# WKUP_CTRL_MMR0_WKUP_CTRL_MMR_CFG0_43000000h register map
Vendor: Texas Instruments
Peripheral module from a debugger description file (folder AM275x).
Registers are 32-bit, read-write, reset 0x0 unless marked. A register's access mark holds for its fields unless they carry their own. Offsets are as the file gives them; lines under a group give offsets from that group; [hi:lo] are bit positions; {n}, {i} and the like mark numbered series; 'fields as' and 'values as' point back to an identical list; <NAME> marks a mode.

## wkup_ctrl_mmr_CFG0 (part 1 of 3)
0x8340 WKUP_CTRL_MMRCFG0_WKUP_WWD0_CTRL — RM WWDT Clock Manager Control Register
  [3:0] WKUP_WWD0_CTRL_WWD_STOP — Controls Clocks to the WWD Watchdog CounterField values (others are reserved):4'b0000 - WWD Counter Running4'b1010 - WWD Counter Stopped Reset Source: mod_g_rst_n
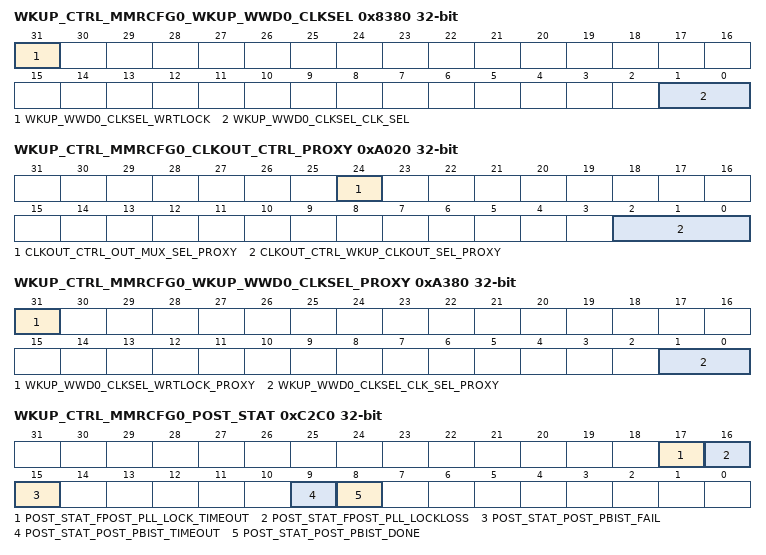
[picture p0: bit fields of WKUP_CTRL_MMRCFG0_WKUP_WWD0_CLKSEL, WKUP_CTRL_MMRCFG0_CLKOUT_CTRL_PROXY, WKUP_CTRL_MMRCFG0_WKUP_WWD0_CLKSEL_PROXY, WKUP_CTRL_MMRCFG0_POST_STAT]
0x8380 WKUP_CTRL_MMRCFG0_WKUP_WWD0_CLKSEL — RM WWDT Clock Manager Clock Selection Register
  [31] WKUP_WWD0_CLKSEL_WRTLOCK — When set, locks WKUP_WWD0_CLKSEL from further writes until the next module reset.Field values (others are reserved):1'b0 - UNLOCKED1'b1 - LOCKED Reset Source: mod_g_rst_n
  [1:0] WKUP_WWD0_CLKSEL_CLK_SEL — Windowed watchdog timer functional clock input select mux controlField values (others are reserved):2'b00 - HFOSC0_CLKOUT2'b01 - DEVICE_CLKOUT_32K2'b10 - CLK_12M_RC2'b11 - CLK_32K Reset Source: mod_g_rst_n
0x8600 WKUP_CTRL_MMRCFG0_WKUP_RTC_CLKSEL — Controls the functional source clock for RTC
  [0] WKUP_RTC_CLKSEL_CLK_SEL — Selects the source of the RTC functional clockField values (others are reserved):1'b0 - DEVICE_CLKOUT_32K1'b1 - CLK_32K_RC Reset Source: mod_por_rst_n
0x9100 WKUP_CTRL_MMRCFG0_CLAIMREG_P2_R0_READONLY ro
  [31:0] CLAIMREG_P2_R0_READONLY — Claim bits for Partition 2 Reset Source: mod_g_rst_n
0x910C WKUP_CTRL_MMRCFG0_CLAIMREG_P2_R3_READONLY ro
  [31:0] CLAIMREG_P2_R3_READONLY — Claim bits for Partition 2 Reset Source: mod_g_rst_n
0x9118 WKUP_CTRL_MMRCFG0_CLAIMREG_P2_R6_READONLY ro
  [31:0] CLAIMREG_P2_R6_READONLY — Claim bits for Partition 2 Reset Source: mod_g_rst_n
0x911C WKUP_CTRL_MMRCFG0_CLAIMREG_P2_R7_READONLY ro
  [31:0] CLAIMREG_P2_R7_READONLY — Claim bits for Partition 2 Reset Source: mod_g_rst_n
0x9130 WKUP_CTRL_MMRCFG0_CLAIMREG_P2_R12_READONLY ro
  [31:0] CLAIMREG_P2_R12_READONLY — Claim bits for Partition 2 Reset Source: mod_g_rst_n
0xA010 WKUP_CTRL_MMRCFG0_WKUP_CLKSEL_PROXY — Selects the functional clock source for the WKUP Domain
  [0] WKUP_CLKSEL_CLK_SEL_PROXY — Selects Clock Source for Wakeup Domain (Device Manager and Peripherals)Field values (others are reserved):1'b0 - CPU_MAIN_PLL15_HSDIV2_CLKOUT__PERIPHERALS_ MAIN_PLL15_HSDIV0_CLKOUT1'b0 - MAIN_PLL15_HSDIV0_CLKOUT0 (HSM_DM_CLK)1'b1 - CPU_AND_PERIPHERALS_MCU_PLL0_HSDIV0_CLKOUT1'b1 - MCU_PLL0_HSDIV0_CKLOUT (MCU_SYSCLK0) Reset Source: mod_g_rst_n
0xA020 WKUP_CTRL_MMRCFG0_CLKOUT_CTRL_PROXY — Enables and selects clock source of WKUP_CLKOUT pin
  [24] CLKOUT_CTRL_OUT_MUX_SEL_PROXY — WKUP CLKOUT (Pin) pin output mux selection. HFOSC0_CLK is a direct output from the HFOSC0Field values (others are reserved):1'b0 - CLK_DIV_OUT1'b1 - HFOSC0_CLK (clk_sel must be DRIVE_LOW) Reset Source: mod_por_rst_n
  [2:0] CLKOUT_CTRL_WKUP_CLKOUT_SEL_PROXY — Controls WKUP CLKOUT MUX for WKUP_CLKOUT0 PinField values (others are reserved):3'b000 - HFOSC0_CLKOUT_SERDES3'b000 - DRIVE_LOW3'b001 - LFOSC0_CLKOUT3'b010 - MAIN_PLL0_HSDIV2_CLKOUT3'b011 - MAIN_PLL1_HSDIV2_CLKOUT3'b100 - MAIN_PLL2_HSDIV9_CLKOUT3'b101 - DEVICE_CLKOUT_32K3'b110 - CLK_12M_RC3'b111 - HFOSC0_CLKOUT Reset Source: mod_por_rst_n
0xA030 WKUP_CTRL_MMRCFG0_WKUP_GTC_CLKSEL_PROXY reset 0x1 — Selects the timebase clock source for the Global Timebase Counter
  [2:0] WKUP_GTC_CLKSEL_CLK_SEL_PROXY — Selects the GTC timebase clock sourceField values (others are reserved):3'b000 - MAIN_PLL2_HSDIV5_CLKOUT3'b001 - MAIN_PLL0_HSDIV6_CLKOUT3'b010 - CP_GEMAC_CPTS0_RFT_CLK (Pin)3'b011 - Reserved '0'3'b100 - MCU_EXT_REFCLK0 (Pin)3'b101 - EXT_REFCLK1 (Pin)3'b110 - MCU_SYSCLK0_DIV23'b110 - MCU_SYSCLK0/23'b111 - MAIN_SYSCLK0 Reset Source: mod_g_rst_n
0xA190 WKUP_CTRL_MMRCFG0_USB0_CLKSEL_PROXY — Selects the functional clock sources for USB0
  [0] USB0_CLKSEL_REFCLK_SEL_PROXY — Selects the clock source for the USB0 ref_clk. Field values (others are reserved):1'b0 - HFOSC0_CLKOUT1'b1 - MAIN_PLL0_HSDIV8_CLKOUT Reset Source: mod_g_rst_n
0xA1B0 WKUP_CTRL_MMRCFG0_WKUP_TIMER0_CLKSEL_PROXY — Timer0 functional clock selection control
  [2:0] WKUP_TIMER0_CLKSEL_CLK_SEL_PROXY — Timer functional clock input select mux controlField values (others are reserved):3'b000 - HFOSC0_CLKOUT3'b001 - DM_CLK/23'b001 - DM_CLK/43'b010 - CLK_12M_RC3'b011 - MCU_PLL0_HSDIV5_CLKOUT3'b100 - MCU_EXT_REFCLK0 (Pin)3'b101 - DEVICE_CLKOUT_32K3'b110 - CPSW0_CPTS_GENF03'b111 - CLK_32K_RC Reset Source: sys_por_rst_n
0xA1B4 WKUP_CTRL_MMRCFG0_WKUP_TIMER1_CLKSEL_PROXY — Timer1 functional clock selection control
  [2:0] WKUP_TIMER1_CLKSEL_CLK_SEL_PROXY — Timer functional clock input select mux controlField values (others are reserved):3'b000 - HFOSC0_CLKOUT3'b001 - DM_CLK/23'b001 - DM_CLK/43'b010 - CLK_12M_RC3'b011 - MCU_PLL0_HSDIV5_CLKOUT3'b100 - MCU_EXT_REFCLK0 (Pin)3'b101 - DEVICE_CLKOUT_32K3'b110 - CPSW0_CPTS_GENF03'b111 - CLK_32K_RC Reset Source: sys_por_rst_n
0xA340 WKUP_CTRL_MMRCFG0_WKUP_WWD0_CTRL_PROXY — RM WWDT Clock Manager Control Register
  [3:0] WKUP_WWD0_CTRL_WWD_STOP_PROXY — Controls Clocks to the WWD Watchdog CounterField values (others are reserved):4'b0000 - WWD Counter Running4'b1010 - WWD Counter Stopped Reset Source: mod_g_rst_n
0xA380 WKUP_CTRL_MMRCFG0_WKUP_WWD0_CLKSEL_PROXY — RM WWDT Clock Manager Clock Selection Register
  [31] WKUP_WWD0_CLKSEL_WRTLOCK_PROXY — When set, locks WKUP_WWD0_CLKSEL from further writes until the next module reset.Field values (others are reserved):1'b0 - UNLOCKED1'b1 - LOCKED Reset Source: mod_g_rst_n
  [1:0] WKUP_WWD0_CLKSEL_CLK_SEL_PROXY — Windowed watchdog timer functional clock input select mux controlField values (others are reserved):2'b00 - HFOSC0_CLKOUT2'b01 - DEVICE_CLKOUT_32K2'b10 - CLK_12M_RC2'b11 - CLK_32K Reset Source: mod_g_rst_n
0xA600 WKUP_CTRL_MMRCFG0_WKUP_RTC_CLKSEL_PROXY — Controls the functional source clock for RTC
  [0] WKUP_RTC_CLKSEL_CLK_SEL_PROXY — Selects the source of the RTC functional clockField values (others are reserved):1'b0 - DEVICE_CLKOUT_32K1'b1 - CLK_32K_RC Reset Source: mod_por_rst_n
{0xB100+4i} WKUP_CTRL_MMRCFG0_CLAIMREG_P2_R{i} (i=0..12)
  [31:0] CLAIMREG_P2_R{i} — Claim bits for Partition 2 Reset Source: mod_g_rst_n
0xC2C0 WKUP_CTRL_MMRCFG0_POST_STAT ro — Contains the result of power-on self tests.
  [17] POST_STAT_FPOST_PLL_LOCK_TIMEOUT — Differentiates between Fast POST and Slow POST. Fast POST is initiated after the PLL locks using the settings in the POST_CFG MMR. Otherwise, if the PLL lock times out, Slow POST is initated at the PLL reference clock rate.Field values (others are reserved):1'b0 - FAST_POST1'b1 - SLOW_POST Reset Source: mod_por_rst_n
  [16] POST_STAT_FPOST_PLL_LOCKLOSS — Indicates that POST exited with a PLL Lockloss ErrorField values (others are reserved):1'b0 - UNKNOWN1'b1 - EXITED_ON_LOCK_LOSS Reset Source: mod_por_rst_n
  [15] POST_STAT_POST_PBIST_FAIL — POST PBIST failedField values (others are reserved):1'b0 - UNKNOWN1'b1 - FAIL Reset Source: mod_por_rst_n
  [9] POST_STAT_POST_PBIST_TIMEOUT — POST PBIST timed outField values (others are reserved):1'b0 - UNKNOWN1'b1 - TIMEOUT Reset Source: mod_por_rst_n
  [8] POST_STAT_POST_PBIST_DONE — POST PBIST doneField values (others are reserved):1'b0 - UNKNOWN1'b1 - DONE Reset Source: mod_por_rst_n
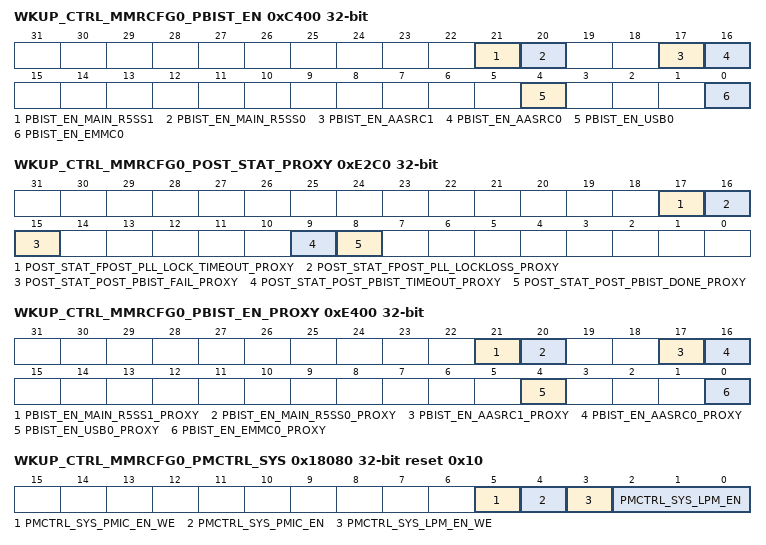
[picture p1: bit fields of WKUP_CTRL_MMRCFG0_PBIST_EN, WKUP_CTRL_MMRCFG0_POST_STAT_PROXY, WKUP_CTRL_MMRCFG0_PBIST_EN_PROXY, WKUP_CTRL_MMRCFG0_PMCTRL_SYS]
0xC400 WKUP_CTRL_MMRCFG0_PBIST_EN — Enables PBIST Config Modes access to memories
  [21] PBIST_EN_MAIN_R5SS1 — Enables PBIST Access to Main R5SS1 MemoriesField values (others are reserved):1'b0 - DISABLE1'b1 - ENABLE Reset Source: mod_g_rst_n
  [20] PBIST_EN_MAIN_R5SS0 — Enables PBIST Access to Main R5SS0 MemoriesField values (others are reserved):1'b0 - DISABLE1'b1 - ENABLE Reset Source: mod_g_rst_n
  [17] PBIST_EN_AASRC1 — Enables PBIST Access to AASRC1 MemoriesField values (others are reserved):1'b0 - DISABLE1'b1 - ENABLE Reset Source: mod_g_rst_n
  [16] PBIST_EN_AASRC0 — Enables PBIST Access to AASRC0 MemoriesField values (others are reserved):1'b0 - DISABLE1'b1 - ENABLE Reset Source: mod_g_rst_n
  [4] PBIST_EN_USB0 — Enables PBIST Access to USB0 MemoriesField values (others are reserved):1'b0 - DISABLE1'b1 - ENABLE Reset Source: mod_g_rst_n
  [0] PBIST_EN_EMMC0 — Enables PBIST Access to MMC0 MemoriesField values (others are reserved):1'b0 - DISABLE1'b1 - ENABLE Reset Source: mod_g_rst_n
{0xD100+4i} WKUP_CTRL_MMRCFG0_CLAIMREG_P3_R{i}_READONLY ro (i=0..8)
  [31:0] CLAIMREG_P3_R{i}_READONLY — Claim bits for Partition 3 Reset Source: mod_g_rst_n
0xE2C0 WKUP_CTRL_MMRCFG0_POST_STAT_PROXY ro — Contains the result of power-on self tests.
  [17] POST_STAT_FPOST_PLL_LOCK_TIMEOUT_PROXY — Differentiates between Fast POST and Slow POST. Fast POST is initiated after the PLL locks using the settings in the POST_CFG MMR. Otherwise, if the PLL lock times out, Slow POST is initated at the PLL reference clock rate.Field values (others are reserved):1'b0 - FAST_POST1'b1 - SLOW_POST Reset Source: mod_por_rst_n
  [16] POST_STAT_FPOST_PLL_LOCKLOSS_PROXY — Indicates that POST exited with a PLL Lockloss ErrorField values (others are reserved):1'b0 - UNKNOWN1'b1 - EXITED_ON_LOCK_LOSS Reset Source: mod_por_rst_n
  [15] POST_STAT_POST_PBIST_FAIL_PROXY — POST PBIST failedField values (others are reserved):1'b0 - UNKNOWN1'b1 - FAIL Reset Source: mod_por_rst_n
  [9] POST_STAT_POST_PBIST_TIMEOUT_PROXY — POST PBIST timed outField values (others are reserved):1'b0 - UNKNOWN1'b1 - TIMEOUT Reset Source: mod_por_rst_n
  [8] POST_STAT_POST_PBIST_DONE_PROXY — POST PBIST doneField values (others are reserved):1'b0 - UNKNOWN1'b1 - DONE Reset Source: mod_por_rst_n
0xE400 WKUP_CTRL_MMRCFG0_PBIST_EN_PROXY — Enables PBIST Config Modes access to memories
  [21] PBIST_EN_MAIN_R5SS1_PROXY — Enables PBIST Access to Main R5SS1 MemoriesField values (others are reserved):1'b0 - DISABLE1'b1 - ENABLE Reset Source: mod_g_rst_n
  [20] PBIST_EN_MAIN_R5SS0_PROXY — Enables PBIST Access to Main R5SS0 MemoriesField values (others are reserved):1'b0 - DISABLE1'b1 - ENABLE Reset Source: mod_g_rst_n
  [17] PBIST_EN_AASRC1_PROXY — Enables PBIST Access to AASRC1 MemoriesField values (others are reserved):1'b0 - DISABLE1'b1 - ENABLE Reset Source: mod_g_rst_n
  [16] PBIST_EN_AASRC0_PROXY — Enables PBIST Access to AASRC0 MemoriesField values (others are reserved):1'b0 - DISABLE1'b1 - ENABLE Reset Source: mod_g_rst_n
  [4] PBIST_EN_USB0_PROXY — Enables PBIST Access to USB0 MemoriesField values (others are reserved):1'b0 - DISABLE1'b1 - ENABLE Reset Source: mod_g_rst_n
  [0] PBIST_EN_EMMC0_PROXY — Enables PBIST Access to MMC0 MemoriesField values (others are reserved):1'b0 - DISABLE1'b1 - ENABLE Reset Source: mod_g_rst_n
{0xF100+4i} WKUP_CTRL_MMRCFG0_CLAIMREG_P3_R{i} (i=0..8)
  [31:0] CLAIMREG_P3_R{i} — Claim bits for Partition 3 Reset Source: mod_g_rst_n
0x11100 WKUP_CTRL_MMRCFG0_CLAIMREG_P4_R0_READONLY ro
  [31:0] CLAIMREG_P4_R0_READONLY — Claim bits for Partition 4 Reset Source: mod_g_rst_n
0x11120 WKUP_CTRL_MMRCFG0_CLAIMREG_P4_R8_READONLY ro
  [31:0] CLAIMREG_P4_R8_READONLY — Claim bits for Partition 4 Reset Source: mod_g_rst_n
{0x13100+4i} WKUP_CTRL_MMRCFG0_CLAIMREG_P4_R{i} (i=0..8)
  [31:0] CLAIMREG_P4_R{i} — Claim bits for Partition 4 Reset Source: mod_g_rst_n
0x18080 WKUP_CTRL_MMRCFG0_PMCTRL_SYS reset 0x10 — Controls operation of the PMIC_LPM_EN pin
  [5] PMCTRL_SYS_PMIC_EN_WE — Unused Field - Value is Don't Care Reset Source: mod_g_rst_n
  [4] PMCTRL_SYS_PMIC_EN — Controls state of PMIC_LPM_EN_OUT when LPM_EN[2:0] is 000 Reset Source: mod_g_rst_n
  [3] PMCTRL_SYS_LPM_EN_WE — Unused Field - Value is Don't Care Reset Source: mod_g_rst_n
  [2:0] PMCTRL_SYS_LPM_EN — Controls whether PMIC_LPM_EN_OUT is driven by the pmic_en bit. Field values (others are reserved):3'b000 - PMIC_LPM_EN_OUT controlled by pmic_en bit. Reset Source: mod_g_rst_n
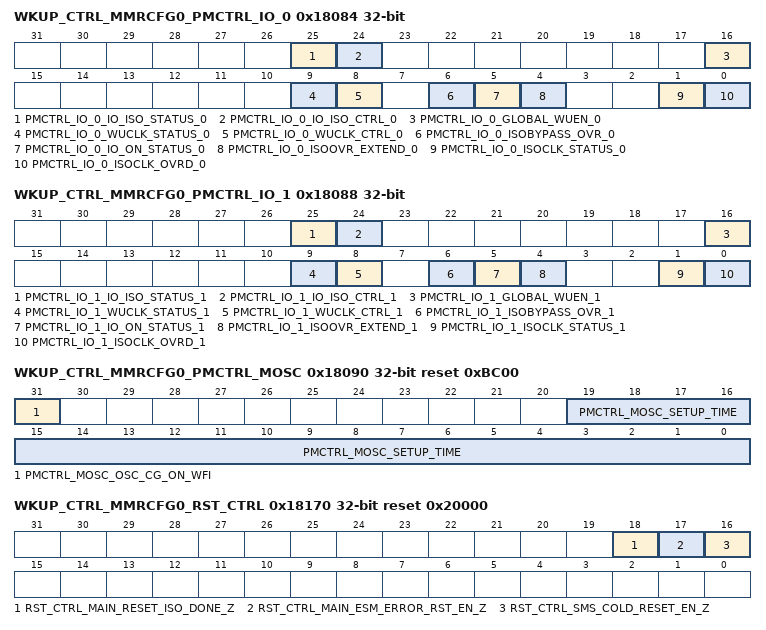
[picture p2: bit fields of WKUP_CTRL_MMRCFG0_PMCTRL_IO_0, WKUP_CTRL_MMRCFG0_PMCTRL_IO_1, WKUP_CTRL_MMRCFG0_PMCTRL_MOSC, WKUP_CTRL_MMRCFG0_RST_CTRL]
0x18084 WKUP_CTRL_MMRCFG0_PMCTRL_IO_0 access per field — This register is writable only when LOCK6-KICK0:1 are unlocked
  [25] PMCTRL_IO_0_IO_ISO_STATUS_0 ro — IO ISO Status. Read 0: IO isolation not active. Read 1: IO isolation active.Reflects value of SMS input port io_isoack coming back fromIO pad ring. Reset Source: mod_g_rst_n
  [24] PMCTRL_IO_0_IO_ISO_CTRL_0 rw — IO ISO control. Writing this bit to 1 will kick off IO isolation. Reset Source: mod_g_rst_n
  [16] PMCTRL_IO_0_GLOBAL_WUEN_0 rw — Global IO wakeup enable. This is a gating condition to allindividual IO WUEN coming from control module. Gating isdone in the Io Logiclogic. 0:All individual IO WUEN are gated in the IO logic (override to 0). 1: All individual IO WUEN from control module are going to IOs.Map to SMS input port io_globalwkupen Reset Source: mod_g_rst_n
  [9] PMCTRL_IO_0_WUCLK_STATUS_0 ro — Reflects value of DM input port io_wuclkack coming backfrom IO pad ring. Reset Source: mod_g_rst_n
  [8] PMCTRL_IO_0_WUCLK_CTRL_0 rw — Direct control on WUCLKIN signal to IO pad ring.0:WUCLKINsignal is driven to 0.IO wakeup daisy chain is functional as wellas IO whose wakeup feature is enabled. 1:WUCLKIN signal is driven to 1. IO wakeup daisy chain is reset and is latching current pad states and WUEN inputs. Reset Source: mod_g_rst_n
  [6] PMCTRL_IO_0_ISOBYPASS_OVR_0 rw — This MMR bit drives directly DM output port io_isobypassundefined. Reset Source: mod_g_rst_n
  [5] PMCTRL_IO_0_IO_ON_STATUS_0 ro — Gives the functional status of the IO ring. Read 0: Part or all of the IOs are not in the ON state that is are in isolation state.Read 1: All IOs are in the ON state.io_on_status = assign 1 if (io_iso == 0 & io_isoack==0 &io_iso_clk == 0 & io_isoclk_ack = 0 ) else 0; Reset Source: mod_g_rst_n
  [4] PMCTRL_IO_0_ISOOVR_EXTEND_0 rw — This drives the SOC chain ISO-OVERRIDE global control.This bit drives directly the DM output port io_isoovrundefined. Atthe SOC level it is used to enable when 1 or gate-off when 0,the individual ISOOR for each IO. This operates as a globalenable/disable for the individual IOs.Control for IO isolation extension.'0' IO isolation is not extended. Transition happens as soon asautomatic restore is completed.'1' IO isolation is extended. The IOs whose ISOOVR bits havebeen individually set in their PADCFG MMRs will all get its IOisolation extended beyond the point when the initial IO daisychain isolation is released. Reset Source: mod_g_rst_n
  [1] PMCTRL_IO_0_ISOCLK_STATUS_0 ro — Reflects value of DM input port io_isoclkack coming backfrom IO pad ring. Reset Source: mod_g_rst_n
  [0] PMCTRL_IO_0_ISOCLK_OVRD_0 rw — Override control on ISOCLKIN signal to IO pad ring.When not overridden this signal is controlled by hardware only.0 ISOCLKIN signal is not override.1 ISOCLKIN signal is overridden to active value ('1'). Reset Source: mod_g_rst_n
0x18088 WKUP_CTRL_MMRCFG0_PMCTRL_IO_1 access per field — This register is writable only when LOCK6-KICK0:1 are unlocked
  [25] PMCTRL_IO_1_IO_ISO_STATUS_1 ro — IO ISO Status. Read 0: IO isolation not active. Read 1: IO isolation active.Reflects value of DM input port io_isoack coming back fromIO pad ring. Reset Source: mod_g_rst_n
  [24] PMCTRL_IO_1_IO_ISO_CTRL_1 rw — IO ISO control. Writing this bit to 1 will kick off IO isolation. Reset Source: mod_g_rst_n
  [16] PMCTRL_IO_1_GLOBAL_WUEN_1 rw — Global IO wakeup enable. This is a gating condition to allindividual IO WUEN coming from control module. Gating isdone in the Spinner logic. 0:All individual IO WUEN are gatedin the Spinner logic (override to 0). 1: All individual IO WUENfrom control module are going to Ios.Map to DM input port io_globalwkupen Reset Source: mod_g_rst_n
  [9] PMCTRL_IO_1_WUCLK_STATUS_1 ro — Reflects value of DM input port io_wuclkack coming backfrom IO pad ring. Reset Source: mod_g_rst_n
  [8] PMCTRL_IO_1_WUCLK_CTRL_1 rw — Direct control on WUCLKIN signal to IO pad ring.0:WUCLKINsignal is driven to 0.IO wakeup daisy chain is functional as wellas IO whose wakeup feature is enabled. 1:WUCLKIN signal is driven to 1. IO wakeup daisy chain is reset and is latching current pad states and WUEN inputs. Reset Source: mod_g_rst_n
  [6] PMCTRL_IO_1_ISOBYPASS_OVR_1 rw — This MMR bit drives directly DM output port io_isobypassundefined. Reset Source: mod_g_rst_n
  [5] PMCTRL_IO_1_IO_ON_STATUS_1 ro — Gives the functional status of the IO ring. Read 0: Part or all ofthe Ios are not in the ON state that is are in isolation state.Read 1: All Ios are in the ON state.io_on_status = assign 1 if (io_iso == 0 & io_isoack==0 &io_iso_clk == 0 & io_isoclk_ack = 0 ) else 0; Reset Source: mod_g_rst_n
  [4] PMCTRL_IO_1_ISOOVR_EXTEND_1 rw — This drives the SOC chain ISO-OVERRIDE global control.This bit drives directly the DM output port io_isoovrundefined. Atthe SOC level it is used to enable when 1 or gate-off when 0,the individual ISOOR for each IO. This operates as a globalenable/disable for the individual IOs.Control for IO isolation extension.'0' IO isolation is not extended. Transition happens as soon asautomatic restore is completed.'1' IO isolation is extended. The IOs whose ISOOVR bits havebeen individually set in their PADCFG MMRs will all get its IOisolation extended beyond the point when the initial IO daisychain isolation is released. Reset Source: mod_g_rst_n
  [1] PMCTRL_IO_1_ISOCLK_STATUS_1 ro — Reflects value of DM input port io_isoclkack coming backfrom IO pad ring. Reset Source: mod_g_rst_n
  [0] PMCTRL_IO_1_ISOCLK_OVRD_1 rw — Override control on ISOCLKIN signal to IO pad ring.When not overridden this signal is controlled by hardware only.0 ISOCLKIN signal is not override.1 ISOCLKIN signal is overridden to active value ('1'). Reset Source: mod_g_rst_n
0x18090 WKUP_CTRL_MMRCFG0_PMCTRL_MOSC reset 0xBC00 — This register is writable only when LOCK6-KICK0:1 are unlocked
  [31] PMCTRL_MOSC_OSC_CG_ON_WFI — To clock gate the main HFOSC, DM sets this bit then enters the WFI state at which time the HFOSC will be gated. Field values (others are reserved):1'b0 - INACTIVE1'b1 - ACTIVE Reset Source: mod_g_rst_n
  [19:0] PMCTRL_MOSC_SETUP_TIME — Number of HFOSC clock cycles before HFOSC clock is ungated to the SOC (allows the HFOSC time to stabilize after starting up, before the SOC is clocked). Reset Source: mod_g_rst_n
0x18098 WKUP_CTRL_MMRCFG0_PM_MISC_STATUS ro — Reflects the progress of the request to clock-gate HFOSCvia MMR PMCTRL_MOSCundefined.
  [1:0] PM_MISC_STATUS_OSC_CG_STAT — HFOSC Clock Gating StateField values (others are reserved):2'b00 - HFOSC_OFF2'b01 - HFOSC_OFF2ON (transition state)2'b10 - HFOSC_ON2OFF (transition state)2'b11 - HFOSC_ON Reset Source: mod_g_rst_n
0x18170 WKUP_CTRL_MMRCFG0_RST_CTRL reset 0x20000 — Controls Reset Assertion and Propogation
  [18] RST_CTRL_MAIN_RESET_ISO_DONE_Z — Blocks Main Domain Warm Reset.Field values (others are reserved):1'b0 - PROPOGATE1'b1 - BLOCK Reset Source: main_chip1_rst_n
  [17] RST_CTRL_MAIN_ESM_ERROR_RST_EN_Z — Block Reset of Main by ESMField values (others are reserved):1'b0 - PROPOGATE1'b1 - BLOCK Reset Source: main_chip1_rst_n
  [16] RST_CTRL_SMS_COLD_RESET_EN_Z — Block Reset of Main by SMSField values (others are reserved):1'b0 - PROPOGATE1'b1 - BLOCK Reset Source: main_chip1_rst_n
0x18174 WKUP_CTRL_MMRCFG0_RST_STAT ro — Reset Status
  [0] RST_STAT_MCU_RESET_ISO_DONE_Z — Indicates MCU Domain is in Reset Isolation When Active (Low)Field values (others are reserved):1'b0 - ISOLATION1'b1 - PASS_THROUGH Reset Source: main_chip1_rst_n
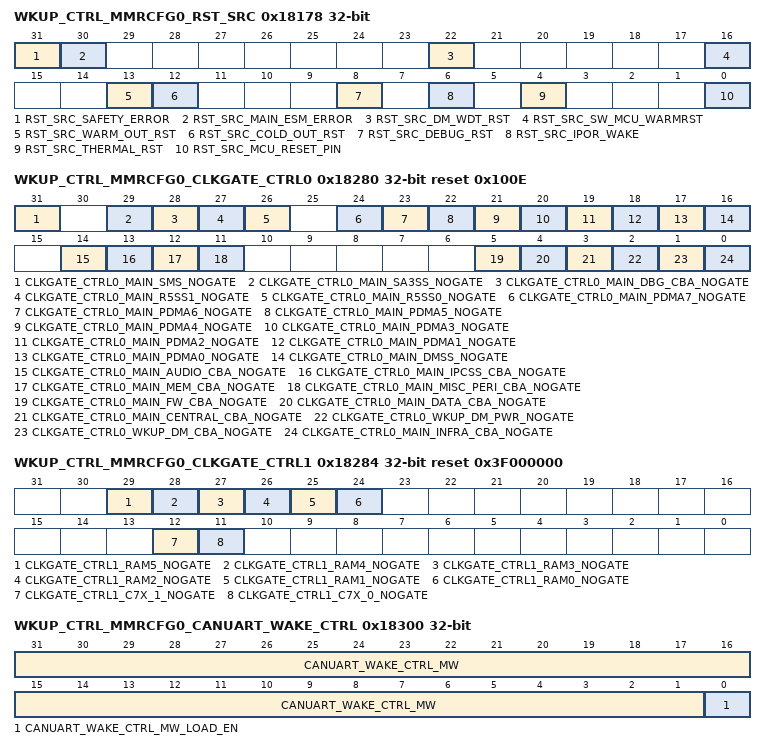
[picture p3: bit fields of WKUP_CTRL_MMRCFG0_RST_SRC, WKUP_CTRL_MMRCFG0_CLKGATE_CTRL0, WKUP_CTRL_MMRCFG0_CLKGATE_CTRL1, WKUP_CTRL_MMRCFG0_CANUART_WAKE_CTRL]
0x18178 WKUP_CTRL_MMRCFG0_RST_SRC ro — Captures Reason for Warm and Main Domain Power On ResetsRead Only Mirror of MCU CTRL MMR version. Clearing these bits must be done through the MCU CTRL MMR.
  [31] RST_SRC_SAFETY_ERROR — Reset Caused by MCU ESM Error. Field values (others are reserved):1'b0 - UNKNOWN1'b1 - DETECTED Reset Source: main_chip1_rst_n
  [30] RST_SRC_MAIN_ESM_ERROR — Reset Caused by Main ESM Error. Field values (others are reserved):1'b0 - UNKNOWN1'b1 - DETECTED Reset Source: main_chip1_rst_n
  [22] RST_SRC_DM_WDT_RST — Watchdog Initiated Reset. Field values (others are reserved):1'b0 - UNKNOWN1'b1 - DETECTED Reset Source: main_chip1_rst_n
  [16] RST_SRC_SW_MCU_WARMRST — Software Warm Reset. Field values (others are reserved):1'b0 - UNKNOWN1'b1 - DETECTED Reset Source: main_chip1_rst_n
  [13] RST_SRC_WARM_OUT_RST — SMS Warm Reset. Field values (others are reserved):1'b0 - UNKNOWN1'b1 - DETECTED Reset Source: main_chip1_rst_n
  [12] RST_SRC_COLD_OUT_RST — SMS Cold Reset. When set, indicates that a SMS Cold reset occurred and reset either MAIN or MCU domains (or both).Field values (others are reserved):1'b0 - UNKNOWN1'b1 - DETECTED Reset Source: main_chip1_rst_n
  [8] RST_SRC_DEBUG_RST — Debug Subsystem Initiated Reset. Field values (others are reserved):1'b0 - UNKNOWN1'b1 - DETECTED Reset Source: main_chip1_rst_n
  [6] RST_SRC_IPOR_WAKE — Wake Event Monitor Internal Power On Reset.Field values (others are reserved):1'b0 - UNKNOWN1'b1 - DETECTED Reset Source: main_chip1_rst_n
  [4] RST_SRC_THERMAL_RST — Thermal Reset. Field values (others are reserved):1'b0 - UNKNOWN1'b1 - DETECTED Reset Source: main_chip1_rst_n
  [0] RST_SRC_MCU_RESET_PIN — Rest Caused by MCU Reset Pin. Field values (others are reserved):1'b0 - UNKNOWN1'b1 - DETECTED Reset Source: main_chip1_rst_n
0x1817C WKUP_CTRL_MMRCFG0_RST_MAGIC_WORD ro — Read Only Mirror of MCU CTRL MMR version.After an MCU_PORz reset this bit field resets to 0x00000000. While this bit field remains 0x00000000 any warm reset from the Main Domain also propagates through the MCU domain.If the application does not require reset isolation of the MCU domain, it may leave this bit field with a value of 0x00000000.If the application does require reset isolation of the MCU domain after the initial boot, then the R5FSS CPU must write a nonzero value to the magic word. The actual value is left to software and different values maybe used to convey information, but in order to isolate the MCU domain from all Main domain warm reset sources that trigger main_resetz, the value must be non-zero.If the value is nonzero and one of the Main domain warm reset sources triggers main_resetz occurs in the main domain, the R5FSS will not be reset. The Main domain bootloader must read this valueto determine that the R5FSS is already initialized, and has configured reset isolation. The Main domain bootloader then also skips any initialization steps involving bootstrapping the R5FSS as it is is already running.Note that MCU_PORz reset is never blocked by a nonzero magic word.
  [31:0] RST_MAGIC_WORD_MCU_MAGIC_WORD — Magic Word Indicating Status of MCU Subsystem Boot Reset Source: main_chip1_rst_n
0x18180 WKUP_CTRL_MMRCFG0_WKUP0_EN — Selects active wake-up sources
  [31:0] WKUP0_EN_WKUPEN — Enables Wakeup from on-chip sources. In addition to values listed, any OR combination of the values is also valid.Field values (others are reserved):32'h00000001 - WKUP_I2C032'h00000002 - WKUP_USART032'h00000004 - MCU_GPIO032'h00000008 - DEBUGundefined - undefined32'h00000020 - WKUP_TIMER032'h00000040 - WKUP_TIMER132'h00000080 - WKUP_RTC32'h00000100 - MAIN_RESET_REQz32'h00000200 - USB0_IN_BANDundefined - undefined32'h00010000 - MAIN_IO_DAISY_CHAIN32'h00020000 - MCU_IO_DAISY_CHAIN32'h00040000 - CANUART_IO_DAISY_CHAIN Reset Source: mod_g_rst_n
0x18280 WKUP_CTRL_MMRCFG0_CLKGATE_CTRL0 reset 0x100E — Controls the power clock gating feature of modules and busses
  [31] CLKGATE_CTRL0_MAIN_SMS_NOGATE — MAIN domain SMS auto clock gate on idle disable. Field values (others are reserved):1'b0 - Auto clock gating enabled1'b1 - Auto clock gating disabled Reset Source: mod_por_rst_n
  [29] CLKGATE_CTRL0_MAIN_SA3SS_NOGATE — MAIN domain SA3SS auto clock gate on idle disable. Field values (others are reserved):1'b0 - Auto clock gating enabled1'b1 - Auto clock gating disabled Reset Source: mod_por_rst_n
  [28] CLKGATE_CTRL0_MAIN_DBG_CBA_NOGATE — MAIN domain Debug CBASS auto clock gate on idle disable. Field values (others are reserved):1'b0 - Auto clock gating enabled1'b1 - Auto clock gating disabled Reset Source: mod_por_rst_n
  [27] CLKGATE_CTRL0_MAIN_R5SS1_NOGATE — MAIN domain R5SS1 auto clock gate on idle disableField values (others are reserved):1'b0 - Auto clock gating enabled1'b1 - Auto clock gating disabled Reset Source: mod_por_rst_n
  [26] CLKGATE_CTRL0_MAIN_R5SS0_NOGATE — MAIN domain R5SS0 auto clock gate on idle disableField values (others are reserved):1'b0 - Auto clock gating enabled1'b1 - Auto clock gating disabled Reset Source: mod_por_rst_n
  [24] CLKGATE_CTRL0_MAIN_PDMA7_NOGATE — MAIN domain PDMA7 (ASRC11) auto clock gate on idle disable. Field values (others are reserved):1'b1 - Auto clock gating disabled Reset Source: mod_por_rst_n
  [23] CLKGATE_CTRL0_MAIN_PDMA6_NOGATE — MAIN domain PDMA6 (ASRC0) auto clock gate on idle disable. Field values (others are reserved):1'b0 - Auto clock gating enabled1'b1 - Auto clock gating disabled1'b0 - Auto clock gating enabled Reset Source: mod_por_rst_n
  [22] CLKGATE_CTRL0_MAIN_PDMA5_NOGATE — MAIN domain PDMA5 (ADC) auto clock gate on idle disable. Field values (others are reserved):1'b0 - Auto clock gating enabled1'b1 - Auto clock gating disabled Reset Source: mod_por_rst_n
  [21] CLKGATE_CTRL0_MAIN_PDMA4_NOGATE — MAIN domain PDMA4 (SPI/MCAN 1) auto clock gate on idle disable. Field values (others are reserved):1'b0 - Auto clock gating enabled1'b1 - Auto clock gating disabled Reset Source: mod_por_rst_n
  [20] CLKGATE_CTRL0_MAIN_PDMA3_NOGATE — MAIN domain PDMA3 (McASP1) auto clock gate on idle disable. Field values (others are reserved):1'b0 - Auto clock gating enabled1'b1 - Auto clock gating disabled Reset Source: mod_por_rst_n
  [19] CLKGATE_CTRL0_MAIN_PDMA2_NOGATE — MAIN domain PDMA2 (McASP0) auto clock gate on idle disable. Field values (others are reserved):1'b0 - Auto clock gating enabled1'b1 - Auto clock gating disabled Reset Source: mod_por_rst_n
  [18] CLKGATE_CTRL0_MAIN_PDMA1_NOGATE — MAIN domain PDMA1 (UART) auto clock gate on idle disable. Field values (others are reserved):1'b0 - Auto clock gating enabled1'b1 - Auto clock gating disabled Reset Source: mod_por_rst_n
  [17] CLKGATE_CTRL0_MAIN_PDMA0_NOGATE — MAIN domain PDMA0 (SPI/MCAN 0) auto clock gate on idle disable. Field values (others are reserved):1'b0 - Auto clock gating enabled1'b1 - Auto clock gating disabled Reset Source: mod_por_rst_n
  [16] CLKGATE_CTRL0_MAIN_DMSS_NOGATE — MAIN domain DMSS auto clock gate on idle disable. Field values (others are reserved):1'b0 - Auto clock gating enabled1'b1 - Auto clock gating disabled Reset Source: mod_por_rst_n
  [14] CLKGATE_CTRL0_MAIN_AUDIO_CBA_NOGATE — MAIN domain Infrastructure bus (AUDIO) auto clock gate on idle disable. Field values (others are reserved):1'b0 - Auto clock gating enabled1'b1 - Auto clock gating disabled Reset Source: mod_por_rst_n
  [13] CLKGATE_CTRL0_MAIN_IPCSS_CBA_NOGATE — MAIN domain Infrastructure CBASS auto clock gate on idle disable. Field values (others are reserved):1'b0 - Auto clock gating enabled1'b1 - Auto clock gating disabled Reset Source: mod_por_rst_n
  [12] CLKGATE_CTRL0_MAIN_MEM_CBA_NOGATE — MAIN domain infrastructure bus (MEM) auto cloclk gate on idle disable Reset Source: mod_por_rst_n
  [11] CLKGATE_CTRL0_MAIN_MISC_PERI_CBA_NOGATE — MAIN domain Infrastructure bus (Misc Peripheral) auto clock gate on idle disable. Field values (others are reserved):1'b0 - Auto clock gating enabled1'b1 - Auto clock gating disabled Reset Source: mod_por_rst_n
  [5] CLKGATE_CTRL0_MAIN_FW_CBA_NOGATE — MAIN domain data bus auto clock gate on idle disable. Field values (others are reserved):1'b0 - Auto clock gating enabled1'b1 - Auto clock gating disabled Reset Source: mod_por_rst_n
  [4] CLKGATE_CTRL0_MAIN_DATA_CBA_NOGATE — MAIN domain data bus auto clock gate on idle disable. Field values (others are reserved):1'b0 - Auto clock gating enabled1'b1 - Auto clock gating disabled Reset Source: mod_por_rst_n
  [3] CLKGATE_CTRL0_MAIN_CENTRAL_CBA_NOGATE — WKUP domain Infrastructure ECC aggregator auto clock gate on idle disable. Field values (others are reserved):1'b0 - Auto clock gating enabled1'b1 - Auto clock gating disabled Reset Source: mod_por_rst_n
  [2] CLKGATE_CTRL0_WKUP_DM_PWR_NOGATE — WKUP domain Device Manager auto clock gate on idle disable.Field values (others are reserved):1'b0 - Auto clock gating enabled1'b1 - Auto clock gating disabled Reset Source: mod_por_rst_n
  [1] CLKGATE_CTRL0_WKUP_DM_CBA_NOGATE — WKUP domain device manager CBA auto clock gate on idle disable.Field values (others are reserved):1'b0 - Auto clock gating enabled1'b1 - Auto clock gating disabled Reset Source: mod_por_rst_n
  [0] CLKGATE_CTRL0_MAIN_INFRA_CBA_NOGATE — MAIN domain Infrastructure bus auto clock gate on idle disable. Field values (others are reserved):1'b0 - Auto clock gating enabled1'b1 - Auto clock gating disabled Reset Source: mod_por_rst_n
0x18284 WKUP_CTRL_MMRCFG0_CLKGATE_CTRL1 reset 0x3F000000 — Controls the power clock gating feature of modules and busses
  [29] CLKGATE_CTRL1_RAM5_NOGATE — MAIN SRAM bank 5 auto clockgate on idle disableField values (others are reserved):1'b0 - Auto clock gating enabled1'b1 - Auto clock gating disabled Reset Source: mod_por_rst_n
  [28] CLKGATE_CTRL1_RAM4_NOGATE — MAIN SRAM bank 4 auto clockgate on idle disableField values (others are reserved):1'b0 - Auto clock gating enabled1'b1 - Auto clock gating disabled Reset Source: mod_por_rst_n
  [27] CLKGATE_CTRL1_RAM3_NOGATE — MAIN SRAM bank 5 auto clockgate on idle disableField values (others are reserved):1'b0 - Auto clock gating enabled1'b1 - Auto clock gating disabled Reset Source: mod_por_rst_n
  [26] CLKGATE_CTRL1_RAM2_NOGATE — MAIN SRAM bank 2 auto clockgate on idle disableField values (others are reserved):1'b0 - Auto clock gating enabled1'b1 - Auto clock gating disabled Reset Source: mod_por_rst_n
  [25] CLKGATE_CTRL1_RAM1_NOGATE — MAIN SRAM bank 1 auto clockgate on idle disableField values (others are reserved):1'b0 - Auto clock gating enabled1'b1 - Auto clock gating disabled Reset Source: mod_por_rst_n
  [24] CLKGATE_CTRL1_RAM0_NOGATE — MAIN SRAM bank 0 auto clockgate on idle disableField values (others are reserved):1'b0 - Auto clock gating enabled1'b1 - Auto clock gating disabled Reset Source: mod_por_rst_n
  [12] CLKGATE_CTRL1_C7X_1_NOGATE — C7x_1 auto clock gate on idle disable. Field values (others are reserved):1'b0 - Auto clock gating enabled1'b1 - Auto clock gating disabled Reset Source: mod_por_rst_n
  [11] CLKGATE_CTRL1_C7X_0_NOGATE — C7x_0 auto clock gate on idle disable. Reset Source: mod_por_rst_n
0x18300 WKUP_CTRL_MMRCFG0_CANUART_WAKE_CTRL — Controls the operation of IO wakeup on the CANUART pins.
  [31:1] CANUART_WAKE_CTRL_MW — CANUART IO magic word. The lower 23 bits determine if the device enters CANUART IO isolation when mw_load_en is set.If the lower 23 bits match the ACTIVATE value (0x5AAAAA), then CANUART IO Isolation is entered, any other value will prevent entry.The upper 8 bits of this register are software defined and do not determine whether or not CANUART IO isolation is entered. Field values (others are reserved):31'h005AAAAA - ACTIVATE31'h00000000 - DEACTIVATE Reset Source: mcu_chip1_rst_n
  [0] CANUART_WAKE_CTRL_MW_LOAD_EN — Magic word load enableSetting this bit loads and locks the mw field for CANUART IO isolation. If the mw field matches ACTIVATE, CANUART IO Isolation is initiated.Field values (others are reserved):1'b0 - UNLOCK1'b1 - LOCK_AND_LOAD Reset Source: mcu_chip1_rst_n
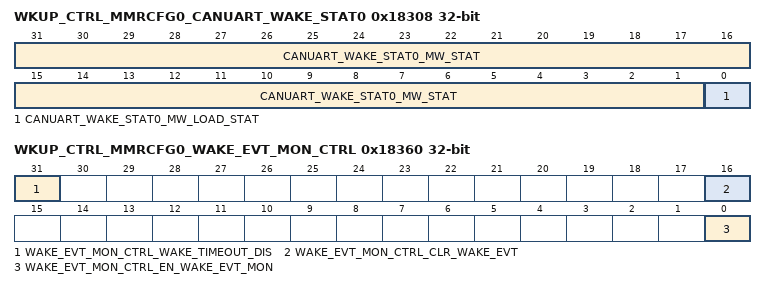
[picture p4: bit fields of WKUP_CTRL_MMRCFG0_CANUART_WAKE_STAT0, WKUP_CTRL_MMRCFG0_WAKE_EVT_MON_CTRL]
0x18308 WKUP_CTRL_MMRCFG0_CANUART_WAKE_STAT0 ro — Provides the status of CANUART_WAKE control bits.These bits come from the daisy-chain wakeup logic and maintain their value across core powerdown if isolation is activated.
  [31:1] CANUART_WAKE_STAT0_MW_STAT — CANUART magic word statusIndicates the latched value of the mw field. Reset Source: mod_por_rst_n
  [0] CANUART_WAKE_STAT0_MW_LOAD_STAT — Magic word load status.Indicates the latched value of the mw_load_en bit Reset Source: mod_por_rst_n
0x1830C WKUP_CTRL_MMRCFG0_CANUART_WAKE_STAT1 ro — Provides CANUART IO isolation status.These bits come from the daisy-chain wakeup logic and maintain their value across core powerdown if isolation is activated
  [0] CANUART_WAKE_STAT1_CANUART_IO_MODE — Indicates if CANUART IO wakeup mode is enabled.Field values (others are reserved):1'b0 - INACTIVE1'b1 - ACTIVATED Reset Source: mod_por_rst_n
0x18310 WKUP_CTRL_MMRCFG0_CANUART_WAKE_OFF_MODE
  [31:0] CANUART_WAKE_OFF_MODE_MW — magic word Reset Source: mod_por_rst_n
0x18318 WKUP_CTRL_MMRCFG0_CANUART_WAKE_OFF_MODE_STAT ro
  [31:0] CANUART_WAKE_OFF_MODE_STAT_MW — returned magic word Reset Source: mod_por_rst_n
0x18320 WKUP_CTRL_MMRCFG0_CANUART_WAKE_RESUME_KEY_j
  [31:0] KEYVAL — key value Reset Source: mod_por_rst_n
0x18340 WKUP_CTRL_MMRCFG0_CANUART_WAKE_RESUME_KEY_STAT_j ro
  [31:0] KEYVAL — returned key value Reset Source: mod_por_rst_n
0x18360 WKUP_CTRL_MMRCFG0_WAKE_EVT_MON_CTRL — Controls monitoring of wake events during IO retention entry/exit
  [31] WAKE_EVT_MON_CTRL_WAKE_TIMEOUT_DIS — Disable wakeup event timeout window. Field values (others are reserved):1'b0 - An Internal POR is generated when a wakeup event is detected by the IORET entry/exit wakeup event monitor before the Immediate Wakeup Timeout window expiration1'b1 - The immediate wakeup timeout window is disabled. Reset Source: mod_por_rst_n
  [16] WAKE_EVT_MON_CTRL_CLR_WAKE_EVT — Clear wakeup events. Write 1 to clear all wakeup events. Read always returns 0.Field values (others are reserved):1'b0 - Read value. Writing 0 has no effect1'b1 - Clear all wake events Reset Source: mod_por_rst_n
  [0] WAKE_EVT_MON_CTRL_EN_WAKE_EVT_MON — Enable wakeup event monitoring. Field values (others are reserved):1'b0 - All IORET entry/exit wakeup event monitoring is disabled1'b1 - Enable wakeup event monitoring during IORET entry/exit. The pins to be monitored are determined by the corresponding PADCONFIG register settings Reset Source: mod_por_rst_n
0x18364 WKUP_CTRL_MMRCFG0_INTRN_POR_DUR reset 0x20 — Determines how long the IPOR generated by IORET entry/exit wakeup monitoring will be asserted
  [7:0] INTRN_POR_DUR_IPOR_LEN — Specifies the number of HFOSC0 clock cycles to assert IPORz (low) when the wake monitoring logic detects a wakeup event. This value must exceed the minimum PORz period for the device with stable power supplies and reference clocks (1200 ns) Reset Source: mod_por_rst_n
